# H3 register map
Vendor: Allwinner; Series: H3; File version: 0.1
CPU: 0, little endian, MPU, no FPU, 0 interrupt priority bits
Registers are 32-bit, read-write, reset 0x0 unless marked. A register's access mark holds for its fields unless they carry their own. Offsets are from the block's base; [hi:lo] are bit positions.

## System_Control
Base 0x01C00000
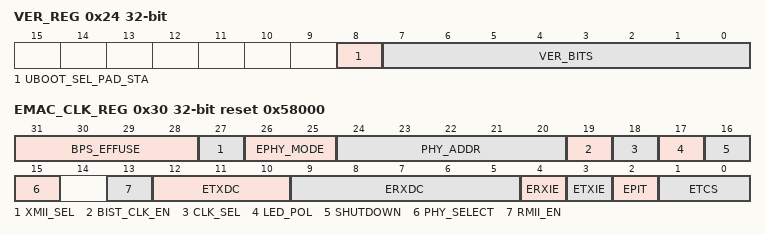
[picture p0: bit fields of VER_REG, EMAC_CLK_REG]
0x24 VER_REG (reset mask 0xFF) — Version Register
  [8] UBOOT_SEL_PAD_STA ro — U_boot Select Pin Status. 0: U_Boot; 1: Normal Boot.
    0=U_Boot; 1=Normal Boot
  [7:0] VER_BITS ro — This read-only bit field always reads back the mask revision level of the chip.
0x30 EMAC_CLK_REG reset 0x58000
  [31:28] BPS_EFFUSE
  [27] XMII_SEL — 0: Internal SMI and MII 1: External SMI and MII
    0=Internal SMI and MII; 1=External SMI and MII
  [26:25] EPHY_MODE — Operation Mode Selection 00 : Normal Mode 01 : Sim Mode 10 : AFE Test Mode 11 : /
  [24:20] PHY_ADDR — PHY Address
  [19] BIST_CLK_EN — 0 : BIST clk disable 1 : BIST clk enable
  [18] CLK_SEL — 0 : 25MHz 1 : 24MHz
  [17] LED_POL — 0 : High active 1 : Low active
  [16] SHUTDOWN — 0 : Power up 1 : Shutdown
  [15] PHY_SELECT — 0 : External PHY 1 : Internal PHY
  [13] RMII_EN — 0 : Disable RMII Module 1 : Enable RMII Module When this bit assert, MII or RGMII interface is disabled( This means bit13 is prior to bit2)
  [12:10] ETXDC — Configure EMAC Transmit Clock Delay Chain.
  [9:5] ERXDC — Configure EMAC Receive Clock Delay Chain.
  [4] ERXIE — Enable EMAC Receive Clock Invertor. 0: Disable 1: Enable
    0=Disable; 1=Enable
  [3] ETXIE — Enable EMAC Transmit Clock Invertor. 0: Disable 1: Enable
    0=Disable; 1=Enable
  [2] EPIT — EMAC PHY Interface Type 0: MII 1: RGMII
    0=MII; 1=RGMII
  [1:0] ETCS — EMAC Transmit Clock Source 00: Transmit clock source for MII 01: External transmit clock source for GMII and RGMII 10: Internal transmit clock source for GMII and RGMII 11: Reserved
    0=Transmit clock source for MII; 1=External transmit clock source for GMII and RGMII; 2=Internal transmit clock source for GMII and RGMII

## High_Speed_Timer
Base 0x01C60000
0x00 HS_TMR_IRQ_EN_REG — HS Timer IRQ Enable Register
  [0] HS_TMR_INT_EN — High Speed Timer Interrupt Enable. 0: No effect; 1: High Speed Timer Interval Value reached interrupt enable.
    0=No_effect; 1=High Speed Timer Interval Value reached interrupt enable
0x04 HS_TMR_IRQ_STAS_REG — HS Timer Status Register
  [0] HS_TMR_IRQ_PEND — High Speed Timer IRQ Pending. Set 1 to the bit will clear it. 0: No effect; 1: Pending, High speed timer interval value is reached.
    0=No_effect; 1=Pending, High speed timer interval value is reached
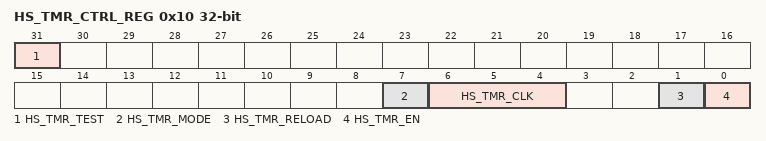
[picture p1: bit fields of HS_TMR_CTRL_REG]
0x10 HS_TMR_CTRL_REG — HS Timer Control Register
  [31] HS_TMR_TEST — High speed timer test mode. In test mode, the low register should be set to 0x1, the high register will down counter. The counter needs to be reloaded. 0: normal mode; 1: test mode.
    0=normal mode;; 1=test mode
  [7] HS_TMR_MODE — High Speed Timer mode. 0: Continuous mode. When interval value reached, the timer will not disable automatically. 1: Single mode. When interval value reached, the timer will disable automatically.
    0=Continuous mode. When interval value reached, the timer will not disable automatically.; 1=Single mode. When interval value reached, the timer will disable automatically.
  [6:4] HS_TMR_CLK — Select the pre-scale of the high speed timer clock sources. 000: /1 001: /2 010: /4 011: /8 100: /16 101: / 110: / 111: /
    0=_slash_1 (/1); 1=_slash_2 (/2); 2=_slash_4 (/4); 3=_slash_8 (/8); 4=_slash_16 (/16)
  [1] HS_TMR_RELOAD — High Speed Timer Reload. 0: No effect, 1: Reload High Speed Timer Interval Value.
    0=No effect, 1: Reload High Speed Timer Interval Value
  [0] HS_TMR_EN — High Speed Timer Enable. 0: Stop/Pause, 1: Start. If the timer is started, it will reload the interval value to internal register, and the current counter will count from interval value to 0. If the current counter does not reach the zero, the timer enable bit is set to `0`, the current value counter will pause. At least wait for 2 cycles, the start bit can be set to 1. In timer pause state, the interval value register can be modified. If the timer is started again, and the Software hope the current value register to down-count from the new interval value, the reload bit and the enable bit should be set to 1 at the same time.
    0=Stop_slash_Pause (Stop/Pause, 1: Start. If the timer is started, it will reload the interval value to internal register, and the current counter will count from interval value to 0. If the current counter does not reach the zero, the timer enable bit is set to `0`, the current value counter will pause. At least wait for 2 cycles, the start bit can be set to 1. In timer pause state, the interval value register can be modified. If the timer is started again, and the Software hope the current value register to down-count from the new interval value, the reload bit and the enable bit should be set to 1 at the same time.)
0x14 HS_TMR_INTV_LO_REG reset not defined — HS Timer Interval Value Low Register
  [31:0] HS_TMR_INTV_VALUE_LO — High Speed Timer Interval Value [31:0].
0x18 HS_TMR_INTV_HI_REG reset not defined — HS Timer Interval Value High Register
  [23:0] HS_TMR_INTV_VALUE_HI — High Speed Timer Interval Value [55:32].
0x1C HS_TMR_CURNT_LO_REG reset not defined — HS Timer Current Value Low Register
  [31:0] HS_TMR_CUR_VALUE_LO — High Speed Timer Current Value [31:0].
0x20 HS_TMR_CURNT_HI_REG reset not defined — HS Timer Current Value High Register
  [23:0] HS_TMR_CUR_VALUE_HI — High Speed Timer Current Value [55:32].
